# TIMER register map
Vendor: Texas Instruments
Peripheral module from a debugger description file (folder UCD3138R032RSM).
Registers are 32-bit, read-write, no defined reset value unless marked. A register's access mark holds for its fields unless they carry their own. Offsets are as the file gives them; lines under a group give offsets from that group; [hi:lo] are bit positions; {n}, {i} and the like mark numbered series; 'fields as' and 'values as' point back to an identical list; <NAME> marks a mode.

## TIMER — mmr_file
0x00 T24CNTDAT ro — 24-bit Counter Data Register
  [23:0] CNT_DAT — Contains the 24-bit counter value
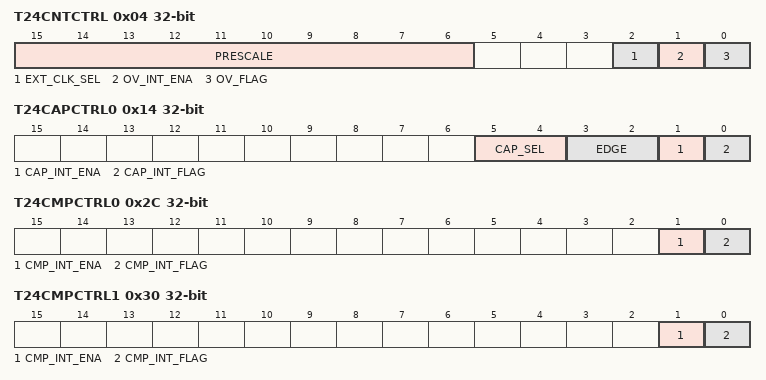
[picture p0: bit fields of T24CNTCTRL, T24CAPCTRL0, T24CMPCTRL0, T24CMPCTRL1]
0x04 T24CNTCTRL access per field — 24-bit Counter Control Register
  [15:6] PRESCALE rw — Prescaler value for 24-bit counter
  [2] EXT_CLK_SEL rw — External Clock Select
  [1] OV_INT_ENA rw — Counter Overflow Interrupt Enable
  [0] OV_FLAG rw — Indicates counter overflow. Overflow event is cleared by writing a 1 to this bit. If a clear and an overflow event occur at the same time, the flag will remain high (set has priority versus clear).
0x08 T24CAPDAT0 ro — Contains the 24-bit input capture value
  [23:0] CAP_DAT
0x14 T24CAPCTRL0 — 24-bit Capture Control Register
  [5:4] CAP_SEL — Capture Pin Select
  [3:2] EDGE — Input Capture Edge Select
  [1] CAP_INT_ENA — Input Capture Interrupt Enable
  [0] CAP_INT_FLAG — Flag which indicates a valid input capture event
0x24 T24CMPDAT0 — 24-bit Capture Output Compare Channel 0 Data Register
  [23:0] CMP_DAT — Contains 24-bit output comparison value
0x28 T24CMPDAT1 — 24-bitOutput Compare Channel 1 Data Register
  [23:0] CMP_DAT — Contains 24-bit output comparison value
0x2C T24CMPCTRL0 — 24-bit Output Compare Channel 0 Control Register
  [1] CMP_INT_ENA — Output Compare Channel Interrupt Enable
  [0] CMP_INT_FLAG — Indicates a valid output compare event. Bit can be cleared by writing a 1 to the bit or by rewriting the 24-bit Output Compare Channel Data Register. If a clear and compare event occur at the same time, the flag will remain high (set has priority versus clear).
0x30 T24CMPCTRL1 — 24-bit Output Compare Channel 1 Control Register
  [1] CMP_INT_ENA — Output Compare Channel Interrupt Enable
  [0] CMP_INT_FLAG — Indicates a valid output compare event
0x34 T16PWM0CNTDATA ro — PWM0 Counter Data Register
  [15:0] CNT_DAT — Contains the 16-bit counter value
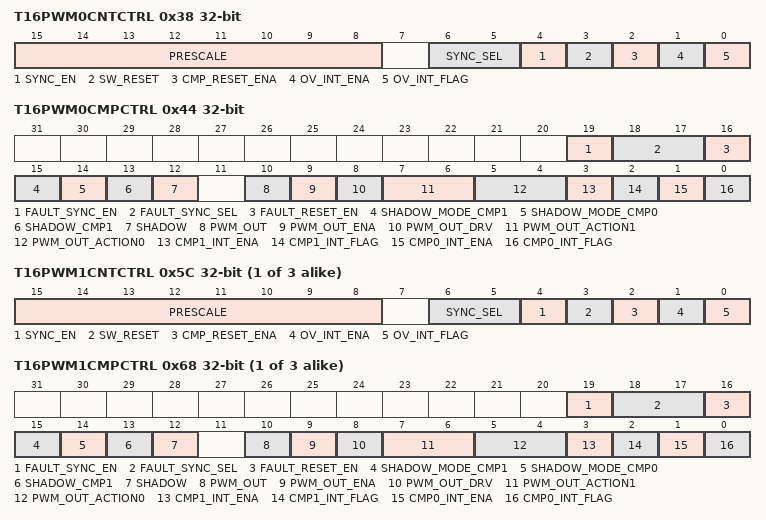
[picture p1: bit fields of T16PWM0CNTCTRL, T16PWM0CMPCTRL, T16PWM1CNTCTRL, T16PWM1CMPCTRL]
0x38 T16PWM0CNTCTRL access per field — PWM0 Counter Control Register
  [15:8] PRESCALE rw — Defines prescaler value to select PWM counter resolution.
  [6:5] SYNC_SEL rw — Configures master PWM counter
  [4] SYNC_EN rw — PWM counter starts when master PWM counter is enabled
  [3] SW_RESET rw — PWM counter reset by software
  [2] CMP_RESET_ENA rw — Enables PWM Counter reset by compare action
  [1] OV_INT_ENA rw — PWM Counter Overflow Interrupt Enable
  [0] OV_INT_FLAG rw — Flag which indicates a PWM counter overflow. This bit is cleared by writing 1 to it. If a clear and an overflow event occur at the same time, the flag will remain high (set has priority versus clear).
0x3C T16PWM0CMP0DAT — PWM0 16-bit Compare Channel 0 Data Register
  [15:0] CMP_DAT — Contains 16-bit compare value
0x40 T16PWM0CMP1DAT — PWM0 16-bit Compare Channel 1 Data Register
  [15:0] CMP_DAT — Contains 16-bit compare value
0x44 T16PWM0CMPCTRL access not given — PWM0 Compare Control Register
  [19] FAULT_SYNC_EN rw — Enables PWM output clear when master PWM has fault
  [18:17] FAULT_SYNC_SEL rw — Configures master PWM
  [16] FAULT_RESET_EN rw — Enables PWM0 output clear when there is fault
  [15] SHADOW_MODE_CMP1 rw — Controls the shadow update mode instant for 16-bit output compare 1 registers
  [14] SHADOW_MODE_CMP0 rw — Controls the shadow update mode instant for 16-bit output compare 0 registers
  [13] SHADOW_CMP1 rw — Controls update of 16-bit output compare 1 registers
  [12] SHADOW rw — Controls update of 16-bit output compare 0 registers
  [10] PWM_OUT rw — Data to be written into the output latch when PWM_OUT_DRV is high
  [9] PWM_OUT_ENA rw — PWM pin configuration
  [8] PWM_OUT_DRV rw — Causes the value of the bit PWM_OUT to be written into the output latch. So it is possible to preload the output latch or to use the pin as GPIO. The compare action has priority before the preload function. This bit is always read as 0
  [7:6] PWM_OUT_ACTION1 rw — Output action for compare 1 event
  [5:4] PWM_OUT_ACTION0 rw — Output action for compare 0 event
  [3] CMP1_INT_ENA rw — Compare 1 Interrupt Enable
  [2] CMP1_INT_FLAG rw — Flag which indicates a valid output compare 1 event. This bit is cleared by writing 1 to this bit or by rewriting T16PWM0CMP1DAT. If a clear and a compare event occurs at the same time, the flag will remain high (set has priority versus write clear).
  [1] CMP0_INT_ENA — Compare 0 Interrupt Enable
  [0] CMP0_INT_FLAG rw — Flag which indicates a valid output compare 0 event. This bit is cleared by writing 1 to this bit or by rewriting T16PWM0CMP0DAT. If a clear and a compare event occurs at the same time, the flag will remain high (set has priority versus write clear).
{0x44+0x14*i} T16PWM{i}CNTDATA ro (i=1..3) — PWM{i} Counter Data Register
  [15:0] CNT_DAT — Contains the 16-bit counter value
{0x48+0x14*i} T16PWM{i}CNTCTRL access per field (i=1..3) — PWM{i} Counter Control Register
  fields as T16PWM0CNTCTRL
{0x4C+0x14*i} T16PWM{i}CMP0DAT (i=1..3) — PWM{i} 16-bit Compare Channel 0 Data Register
  [15:0] CMP_DAT — Contains 16-bit compare value
{0x50+0x14*i} T16PWM{i}CMP1DAT (i=1..3) — PWM{i} 16-bit Compare Channel 1 Data Register
  [15:0] CMP_DAT — Contains 16-bit compare value
{0x54+0x14*i} T16PWM{i}CMPCTRL access not given (i=1..3) — PWM{i} Compare Control Register
  [19] FAULT_SYNC_EN rw — Enables PWM output clear when master PWM has fault
  [18:17] FAULT_SYNC_SEL rw — Configures master PWM
  [16] FAULT_RESET_EN rw — Enables PWM{i} output clear when there is fault
  [15] SHADOW_MODE_CMP1 rw — Controls the shadow update mode instant for 16-bit output compare 1 registers
  [14] SHADOW_MODE_CMP0 rw — Controls the shadow update mode instant for 16-bit output compare 0 registers
  [13] SHADOW_CMP1 rw — Controls update of 16-bit output compare 1 registers
  [12] SHADOW rw — Controls update of 16-bit output compare 0 registers
  [10] PWM_OUT rw — Data to be written into the output latch when PWM_OUT_DRV is high
  [9] PWM_OUT_ENA rw — PWM pin configuration
  [8] PWM_OUT_DRV rw — Causes the value of the bit PWM_OUT to be written into the output latch. So it is possible to preload the output latch or to use the pin as GPIO. The compare action has priority before the preload function. This bit is always read as 0
  [7:6] PWM_OUT_ACTION1 rw — Output action for compare 1 event
  [5:4] PWM_OUT_ACTION0 rw — Output action for compare 0 event
  [3] CMP1_INT_ENA rw — Compare 1 Interrupt Enable
  [2] CMP1_INT_FLAG rw — Flag which indicates a valid output compare 1 event. This bit is cleared by writing 1 to this bit or by rewriting T16PWM{i}CMP1DAT. If a clear and a compare event occurs at the same time, the flag will remain high (set has priority versus write clear).
  [1] CMP0_INT_ENA — Compare 0 Interrupt Enable
  [0] CMP0_INT_FLAG rw — Flag which indicates a valid output compare 0 event. This bit is cleared by writing 1 to this bit or by rewriting T16PWM{i}CMP0DAT. If a clear and a compare event occurs at the same time, the flag will remain high (set has priority versus write clear).
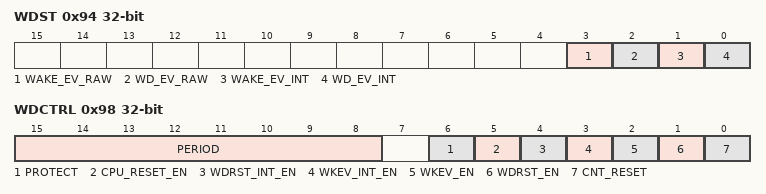
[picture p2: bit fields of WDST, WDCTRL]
0x94 WDST ro — Watchdog Status
  [3] WAKE_EV_RAW — Watchdog wake event raw status
  [2] WD_EV_RAW — Watchdog eventraw status
  [1] WAKE_EV_INT — Watchdog wakeup event interrupt status. Cleared on read of Watchdog Status Register
  [0] WD_EV_INT — Watchdog event interrupt status. Cleared on read of Watchdog Status Register
0x98 WDCTRL access per field — Watchdog Control
  [15:8] PERIOD rw — Configures time for watchdog reset
  [6] PROTECT rw — Watchdog Protect Bit, Active Low
  [5] CPU_RESET_EN rw — Enables Watchdog reset event to reset the CPU
  [4] WDRST_INT_EN rw — Watchdog Reset Event Interrupt Enable
  [3] WKEV_INT_EN rw — Watchdog Wake Event Interrupt Enable
  [2] WKEV_EN rw — Watchdog Wake Event Comparator Enable
  [1] WDRST_EN rw — Watchdog Reset Event Comparator Enable
  [0] CNT_RESET rw — Resets watchdog counter
0x9C TESTMODULE — Test Register
  [31:0] TEST_DAT — Test data
